# MCASP8_CFG_TARG register map
Vendor: Texas Instruments
Peripheral module from a debugger description file (folder am572x).
Registers are 32-bit, read-only, reset 0x0 unless marked. A register's access mark holds for its fields unless they carry their own. Offsets are as the file gives them; lines under a group give offsets from that group; [hi:lo] are bit positions; {n}, {i} and the like mark numbered series; 'fields as' and 'values as' point back to an identical list; <NAME> marks a mode.

## MCASP8_CFG_TARG
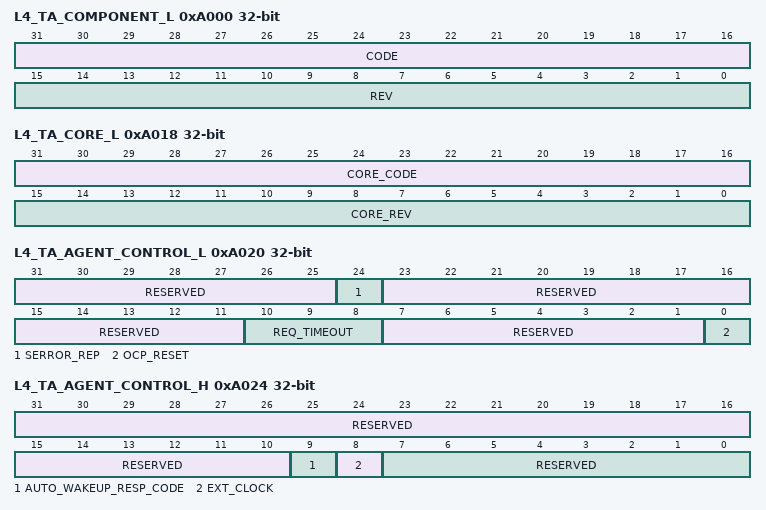
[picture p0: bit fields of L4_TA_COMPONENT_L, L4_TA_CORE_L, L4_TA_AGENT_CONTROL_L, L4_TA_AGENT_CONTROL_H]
0xA000 L4_TA_COMPONENT_L reset not defined — Contains a component code and revision.
  [31:16] CODE — Interconnect code.
  [15:0] REV — Component revision code.
0xA004 L4_TA_COMPONENT_H — Contains a component code and revision.
  [31:0] RESERVED — Read returns 0
0xA018 L4_TA_CORE_L reset not defined — Contains a component code and revision.
  [31:16] CORE_CODE — Interconnect core code
  [15:0] CORE_REV — Component revision code code
0xA01C L4_TA_CORE_H (reset mask 0xFFFF0000) — Contains a component code and revision.
  [15:0] VENDOR_CODE — Vendor revision core code
0xA020 L4_TA_AGENT_CONTROL_L access not given (reset mask 0xFF0007FF) — Enable error reporting
  [31:25] RESERVED ro — Read returns 0.
  [24] SERROR_REP ro — Enable logging of error
  [23:11] RESERVED — Read returns 0. (access UNDEFINED_TYPE_STRING)
  [10:8] REQ_TIMEOUT rw — Time-out Bound. Values are: 0 - No time-out 1 - 1x base cycles. 2 - 4x base cycles. 3 - 16x base cycles. 4 - 64x base cycles.
  [7:1] RESERVED ro — Read returns 0.
  [0] OCP_RESET rw — The OCP_RESET field controls the OCP reset signal to the attached core. Setting this bit clears any pending transfers and resets the OCP interface. The bit must be cleared to deassert the OCP reset signal. When the software reset feature is available on a target agent, the target agent OCP must also have a reset signal directed to the target core.
0xA024 L4_TA_AGENT_CONTROL_H — Enable clock power management
  [31:10] RESERVED — Read returns 0.
  [9] AUTO_WAKEUP_RESP_CODE
  [8] EXT_CLOCK — When set to 1, the ext_clk_off_i signal on a target agent indicates when the target agent should shut off.
  [7:0] RESERVED — Read returns 0.
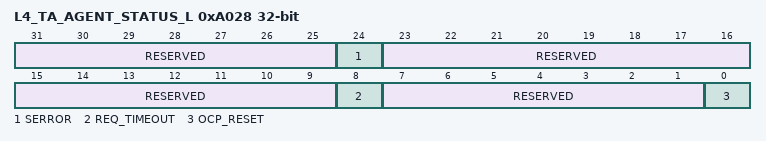
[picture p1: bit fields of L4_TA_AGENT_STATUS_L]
0xA028 L4_TA_AGENT_STATUS_L access not given — Error reporting
  [31:25] RESERVED ro — Read returns 0.
  [24] SERROR ro — Value of OCP SError signal
  [23:9] RESERVED ro — Read returns 0.
  [8] REQ_TIMEOUT — Time-out status: 0x0: No request time-out 0x1: A request time-out has occurred (access R 1toCLR)
  [7:1] RESERVED ro — Read returns 0.
  [0] OCP_RESET ro — L3 Reset
0xA02C L4_TA_AGENT_STATUS_H — Error reporting
  [31:0] RESERVED — Read returns 0
